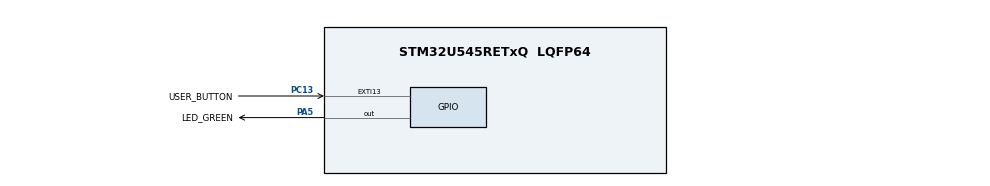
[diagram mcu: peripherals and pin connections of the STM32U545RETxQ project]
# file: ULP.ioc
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CORTEX_M33_NS.userName=CORTEX_M33
Mcu.Family=STM32U5
Mcu.Name=STM32U545RETxQ
Mcu.Package=LQFP64
NVIC.PriorityGroup=NVIC_PRIORITYGROUP_4
NVIC.RTC_IRQn=true\:0\:0\:false\:false\:true\:true\:true\:true
PA5.GPIO_Label=LED_GREEN
PA5.GPIO_PuPd=GPIO_PULLUP
PA5.GPIO_Speed=GPIO_SPEED_FREQ_HIGH
PA5.Signal=GPIO_Output
PC13.GPIO_Label=USER_BUTTON
PC13.GPIO_ModeDefaultEXTI=GPIO_MODE_IT_FALLING
PC13.Signal=GPXTI13
PWR.PowerMode=PWR_SMPS_SUPPLY
ProjectManager.HeapSize=0x200
ProjectManager.StackSize=0x400
ProjectManager.TargetToolchain=STM32CubeIDE
RCC.ADCFreq_Value=16000000
RCC.DACCLockSelectionVirtual=RCC_DAC1CLKSOURCE_LSI
RCC.DACCLockSelectionVirtualString=RCC_DAC1CLKSOURCE_LSI
RCC.EPOD_VALUE=4000000
RCC.HSE_VALUE=16000000
RCC.HSI48_VALUE=48000000
RCC.HSI_VALUE=16000000
RCC.LSE_VALUE=32768
RCC.LSIDIV_VALUE=32000
RCC.MSI_VALUE=4000000
RCC.USBFreq_Value=48000000
RCC.VCOOutputFreq_Value=516000000
RTC.WakeUpClock-WakeUp=RTC_WAKEUPCLOCK_CK_SPRE_16BITS
RTC.WakeUpCounter-WakeUp=2
VP_ICACHE_VS_ICACHE.Mode=DirectMappedCache
VP_LPBAMQUEUE_VS_QUEUE.Mode=QUEUEMODE
VP_LPBAM_VS_SIG1.Mode=SmartRun
VP_LPBAM_VS_SIG4.Mode=LPDMA1
VP_MEMORYMAP_VS_MEMORYMAP.Mode=CurAppReg
VP_PWR_VS_LPOM.Mode=PowerOptimisation
VP_PWR_VS_SECSignals.Mode=Security/Privilege
VP_RTC_VS_RTC_Activate.Mode=RTC_Enabled
VP_RTC_VS_RTC_WakeUp_intern.Mode=WakeUp
board=NUCLEO-U545RE-Q

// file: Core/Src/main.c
/* USER CODE BEGIN Header */
/**
  ******************************************************************************
  * @file           : main.c
  * @brief          : Main program body
  ******************************************************************************
  * @attention
  *
  * Copyright (c) 2024 STMicroelectronics.
  * All rights reserved.
  *
  * This software is licensed under terms that can be found in the LICENSE file
  * in the root directory of this software component.
  * If no LICENSE file comes with this software, it is provided AS-IS.
  *
  ******************************************************************************
  */
/* USER CODE END Header */
#include "main.h"

RTC_HandleTypeDef hrtc;

void SystemClock_Config(void);
static void SystemPower_Config(void);
static void MX_GPIO_Init(void);
static void MX_ICACHE_Init(void);
static void MX_RTC_Init(void);

int main(void)
{

  /* MCU Configuration--------------------------------------------------------*/

  /* Reset of all peripherals, Initializes the Flash interface and the Systick. */
  HAL_Init();

  /* Configure the system clock */
  SystemClock_Config();

  /* Configure the System Power */
  SystemPower_Config();

  /* Initialize all configured peripherals */
  MX_GPIO_Init();
  MX_ICACHE_Init();
  MX_RTC_Init();
  /* USER CODE BEGIN 2 */

  /* 1 - Measure consumption in Run LDO operation*/
  HAL_Delay(2000);

  /* 2 - Measure consumption in Run SMPS operation */
  /* The SMPS regulator supplies the Vcore Power Domains */
  HAL_PWREx_ConfigSupply(PWR_SMPS_SUPPLY);
  HAL_Delay(2000);

  /* 3 - Measure consumption for Power-down Mode for Flash Banks */
  /* Enable the Power-down Mode for Flash Banks*/
  HAL_FLASHEx_EnablePowerDown(FLASH_BANK_2);
  HAL_Delay(2000);

  /* Enable ultra low power mode */
  HAL_PWREx_EnableUltraLowPowerMode();

  /* Enable the Autonomous Mode for the RTC Stop0/1/2 */
  __HAL_RCC_RTCAPB_CLKAM_ENABLE();

  /* Set RTC wakeup timer for 2s */
  HAL_RTCEx_SetWakeUpTimer_IT(&hrtc, 2, RTC_WAKEUPCLOCK_CK_SPRE_16BITS, 0);

  /* 4 - Measure consumption in Stop 2 mode Full SRAM retention */
  /* Enter in Stop 2 mode */
  HAL_PWREx_EnterSTOP2Mode(PWR_STOPENTRY_WFI);

  /* Disable RAM page(s) content lost in Stop mode (Stop 0, 1, 2, 3) */
   HAL_PWREx_DisableRAMsContentStopRetention(PWR_SRAM1_FULL_STOP_RETENTION);

   HAL_PWREx_DisableRAMsContentStopRetention(PWR_SRAM2_FULL_STOP_RETENTION);

   HAL_PWREx_DisableRAMsContentStopRetention(PWR_ICACHE_FULL_STOP_RETENTION);

   HAL_PWREx_DisableRAMsContentStopRetention(PWR_DCACHE1_FULL_STOP_RETENTION);

   HAL_PWREx_DisableRAMsContentStopRetention(PWR_PERIPHRAM_FULL_STOP_RETENTION);

   HAL_PWREx_DisableRAMsContentStopRetention(PWR_PKA32RAM_FULL_STOP_RETENTION);
  /* USER CODE END 2 */

  /* Infinite loop */
  while (1)
  {

    /* USER CODE BEGIN 3 */
	    /* Led Toggling */
	    HAL_GPIO_TogglePin(GPIOA, GPIO_PIN_5);
	    HAL_Delay(100);
	    HAL_GPIO_TogglePin(GPIOA, GPIO_PIN_5);

	    /* Set RTC wakeup timer for 2s */
	    HAL_RTCEx_SetWakeUpTimer_IT(&hrtc, 5, RTC_WAKEUPCLOCK_CK_SPRE_16BITS, 0);

	    /* 5 - Measure consumption in Stop 2 mode reduced SRAM retention*/
	    /* Enter in Stop 2 mode */
	    HAL_PWREx_EnterSTOP2Mode(PWR_STOPENTRY_WFI);
  }
  /* USER CODE END 3 */
}

void SystemClock_Config(void)
{
  RCC_OscInitTypeDef RCC_OscInitStruct = {0};
  RCC_ClkInitTypeDef RCC_ClkInitStruct = {0};

  /** Configure the main internal regulator output voltage
  */
  if (HAL_PWREx_ControlVoltageScaling(PWR_REGULATOR_VOLTAGE_SCALE4) != HAL_OK)
  {
    Error_Handler();
  }

  /** Initializes the CPU, AHB and APB buses clocks
  */
  RCC_OscInitStruct.OscillatorType = RCC_OSCILLATORTYPE_LSI|RCC_OSCILLATORTYPE_MSI;
  RCC_OscInitStruct.LSIState = RCC_LSI_ON;
  RCC_OscInitStruct.MSIState = RCC_MSI_ON;
  RCC_OscInitStruct.MSICalibrationValue = RCC_MSICALIBRATION_DEFAULT;
  RCC_OscInitStruct.MSIClockRange = RCC_MSIRANGE_4;
  RCC_OscInitStruct.LSIDiv = RCC_LSI_DIV1;
  RCC_OscInitStruct.PLL.PLLState = RCC_PLL_NONE;
  if (HAL_RCC_OscConfig(&RCC_OscInitStruct) != HAL_OK)
  {
    Error_Handler();
  }

  /** Initializes the CPU, AHB and APB buses clocks
  */
  RCC_ClkInitStruct.ClockType = RCC_CLOCKTYPE_HCLK|RCC_CLOCKTYPE_SYSCLK
                              |RCC_CLOCKTYPE_PCLK1|RCC_CLOCKTYPE_PCLK2
                              |RCC_CLOCKTYPE_PCLK3;
  RCC_ClkInitStruct.SYSCLKSource = RCC_SYSCLKSOURCE_MSI;
  RCC_ClkInitStruct.AHBCLKDivider = RCC_SYSCLK_DIV1;
  RCC_ClkInitStruct.APB1CLKDivider = RCC_HCLK_DIV1;
  RCC_ClkInitStruct.APB2CLKDivider = RCC_HCLK_DIV1;
  RCC_ClkInitStruct.APB3CLKDivider = RCC_HCLK_DIV1;

  if (HAL_RCC_ClockConfig(&RCC_ClkInitStruct, FLASH_LATENCY_0) != HAL_OK)
  {
    Error_Handler();
  }
}

/**
  * @brief Power Configuration
  * @retval None
  */
static void SystemPower_Config(void)
{

  /*
   * Switch to SMPS regulator instead of LDO
   */
  if (HAL_PWREx_ConfigSupply(PWR_SMPS_SUPPLY) != HAL_OK)
  {
    Error_Handler();
  }
}

static void MX_ICACHE_Init(void)
{

  /** Enable instruction cache in 1-way (direct mapped cache)
  */
  if (HAL_ICACHE_ConfigAssociativityMode(ICACHE_1WAY) != HAL_OK)
  {
    Error_Handler();
  }
  if (HAL_ICACHE_Enable() != HAL_OK)
  {
    Error_Handler();
  }

}

static void MX_RTC_Init(void)
{

  RTC_PrivilegeStateTypeDef privilegeState = {0};

  /** Initialize RTC Only
  */
  hrtc.Instance = RTC;
  hrtc.Init.HourFormat = RTC_HOURFORMAT_24;
  hrtc.Init.AsynchPrediv = 127;
  hrtc.Init.SynchPrediv = 255;
  hrtc.Init.OutPut = RTC_OUTPUT_DISABLE;
  hrtc.Init.OutPutRemap = RTC_OUTPUT_REMAP_NONE;
  hrtc.Init.OutPutPolarity = RTC_OUTPUT_POLARITY_HIGH;
  hrtc.Init.OutPutType = RTC_OUTPUT_TYPE_OPENDRAIN;
  hrtc.Init.OutPutPullUp = RTC_OUTPUT_PULLUP_NONE;
  hrtc.Init.BinMode = RTC_BINARY_NONE;
  if (HAL_RTC_Init(&hrtc) != HAL_OK)
  {
    Error_Handler();
  }
  privilegeState.rtcPrivilegeFull = RTC_PRIVILEGE_FULL_NO;
  privilegeState.backupRegisterPrivZone = RTC_PRIVILEGE_BKUP_ZONE_NONE;
  privilegeState.backupRegisterStartZone2 = RTC_BKP_DR0;
  privilegeState.backupRegisterStartZone3 = RTC_BKP_DR0;
  if (HAL_RTCEx_PrivilegeModeSet(&hrtc, &privilegeState) != HAL_OK)
  {
    Error_Handler();
  }

  /** Enable the WakeUp
  */
  if (HAL_RTCEx_SetWakeUpTimer_IT(&hrtc, 2, RTC_WAKEUPCLOCK_CK_SPRE_16BITS, 0) != HAL_OK)
  {
    Error_Handler();
  }

}

static void MX_GPIO_Init(void)
{
  GPIO_InitTypeDef GPIO_InitStruct = {0};

  /* GPIO Ports Clock Enable */
  __HAL_RCC_GPIOC_CLK_ENABLE();
  __HAL_RCC_GPIOA_CLK_ENABLE();

  /*Configure GPIO pin Output Level */
  HAL_GPIO_WritePin(LED_GREEN_GPIO_Port, LED_GREEN_Pin, GPIO_PIN_RESET);

  /*Configure GPIO pin : USER_BUTTON_Pin */
  GPIO_InitStruct.Pin = USER_BUTTON_Pin;
  GPIO_InitStruct.Mode = GPIO_MODE_IT_FALLING;
  GPIO_InitStruct.Pull = GPIO_NOPULL;
  HAL_GPIO_Init(USER_BUTTON_GPIO_Port, &GPIO_InitStruct);

  /*Configure GPIO pin : LED_GREEN_Pin */
  GPIO_InitStruct.Pin = LED_GREEN_Pin;
  GPIO_InitStruct.Mode = GPIO_MODE_OUTPUT_PP;
  GPIO_InitStruct.Pull = GPIO_PULLUP;
  GPIO_InitStruct.Speed = GPIO_SPEED_FREQ_HIGH;
  HAL_GPIO_Init(LED_GREEN_GPIO_Port, &GPIO_InitStruct);

}

void Error_Handler(void)
{
  __disable_irq();
  while (1)
  {
  }
}
